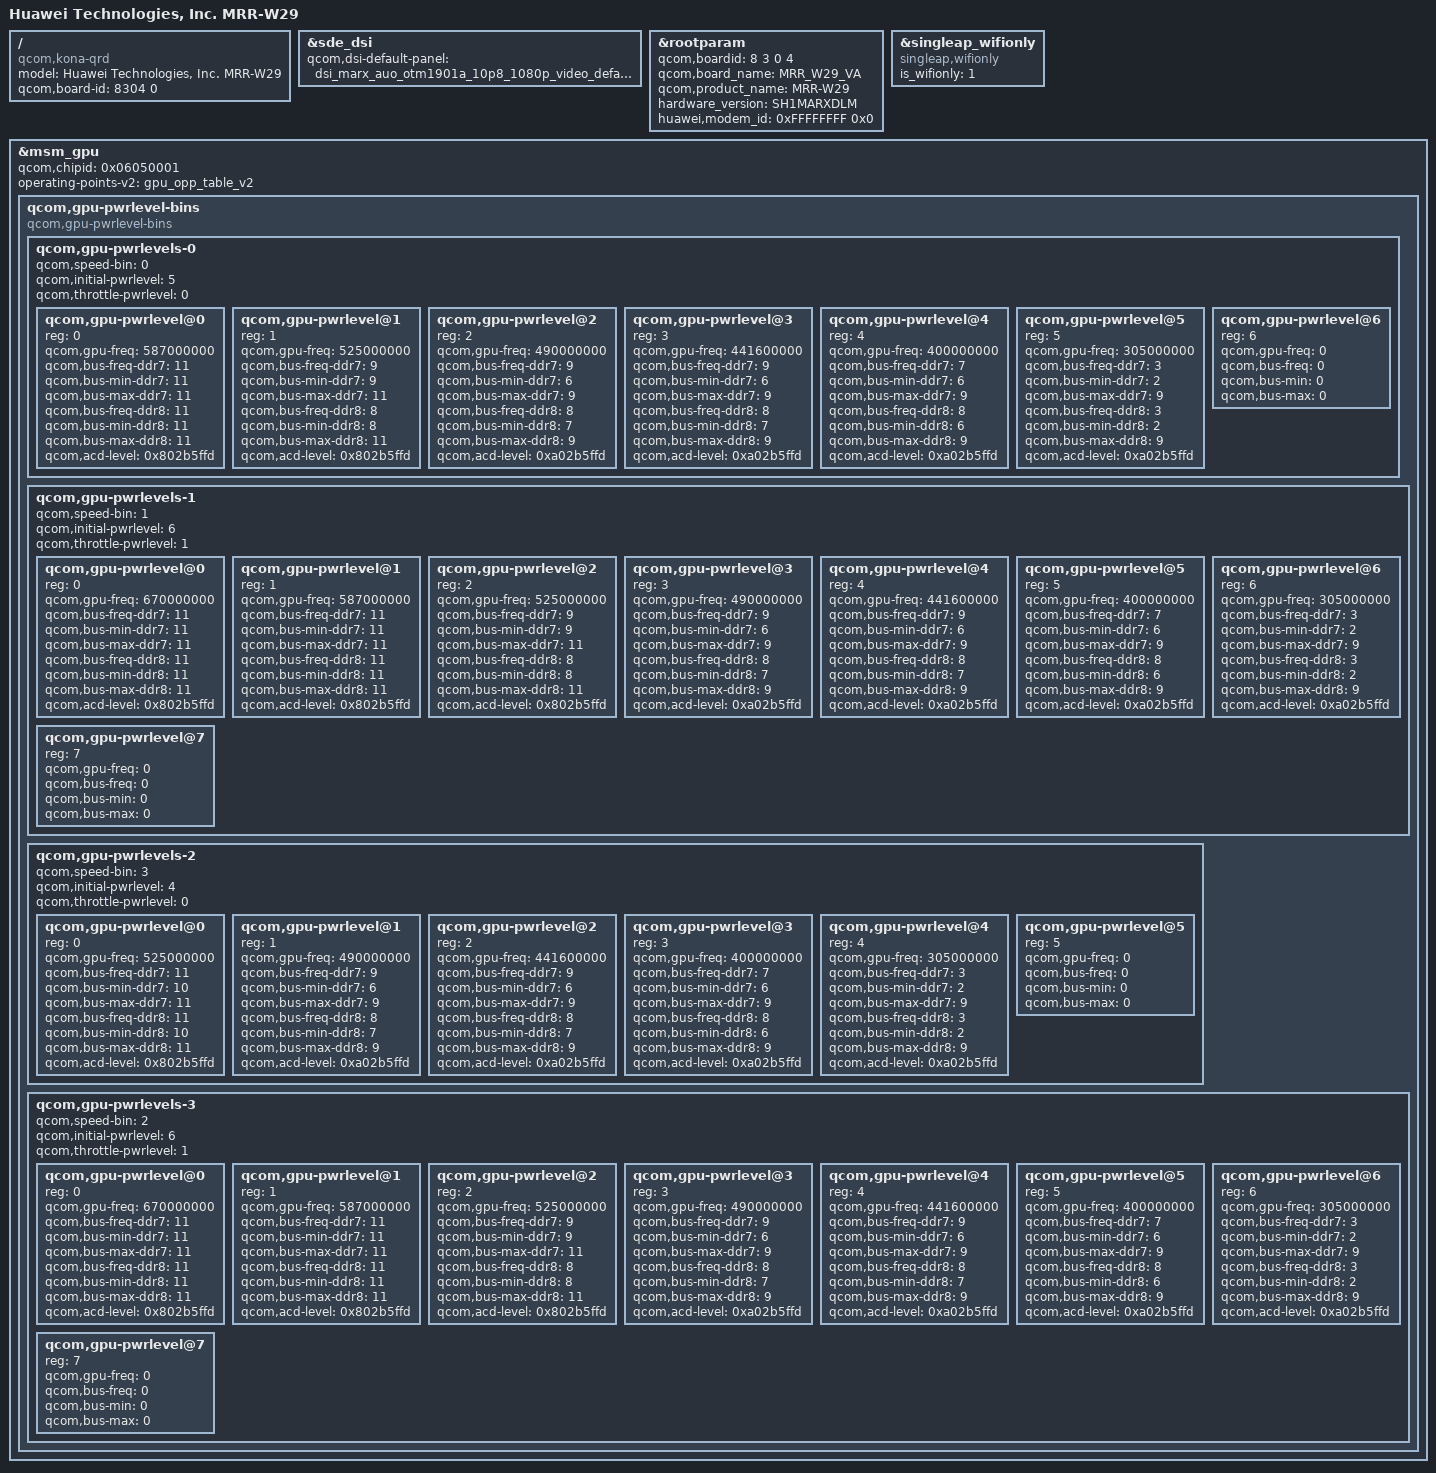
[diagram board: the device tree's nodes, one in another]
/dts-v1/;
/plugin/;

#include "../../common/common.dtsi"
#include "huawei-lcd.dtsi"
#include "huawei_tp.dtsi"
#include "../common/huawei_charger.dtsi"
#include "../common/huawei_pcie.dtsi"
#include "huawei-audio.dtsi"
#include "huawei-sensor.dtsi"
#include "huawei-vibrator.dtsi"
#include "huawei_antenna_board_detect.dtsi"
#include "huawei_camera.dtsi"
#include "huawei_wifi.dtsi"
#include "huawei_storage.dtsi"
#include "huawei_dev_detect.dtsi"
#include "../common/huawei_usb.dtsi"

/ {
    /* bsp_replace_info @ model = "Huawei Technologies, Inc. %product_name%"; */
    model = "Huawei Technologies, Inc. MRR-W29";
    compatible = "qcom,kona-qrd", "qcom,kona", "qcom,qrd";
    /* bsp_replace_info @ qcom,board-id = <%boardid% 0>; */
    qcom,board-id = <8304 0>;
};

&sde_dsi {
    qcom,dsi-default-panel = <&dsi_marx_auo_otm1901a_10p8_1080p_video_default>;
};

&rootparam {
    /* bsp_replace_info @ qcom,boardid = <%boardid_split%>; */
    /* auto_key_info @ name: boardid type: uint32 default: 0 */
    qcom,boardid = <8 3 0 4>;
    /* bsp_replace_info @ qcom,board_name = "%board_name%"; */
    qcom,board_name = "MRR_W29_VA";
    /* bsp_replace_info @ qcom,product_name = "%product_name%"; */
    qcom,product_name = "MRR-W29";
    /* bsp_replace_info @ hardware_version = "%hardware_version%"; */
    hardware_version = "SH1MARXDLM";
    /* bsp_replace_info @ huawei,modem_id = <%modem_id% 0x0>; */
    huawei,modem_id = <0xFFFFFFFF 0x0>;
};

&singleap_wifionly {
    compatible = "singleap,wifionly";
    is_wifionly = "1";
    status = "ok";
};

&msm_gpu {
	qcom,chipid = <0x06050001>;

	/* GPU OPP data */
	operating-points-v2 = <&gpu_opp_table_v2>;

	/delete-property/qcom,initial-pwrlevel;
	/delete-node/qcom,gpu-pwrlevels;

	/* Power levels bins */
	qcom,gpu-pwrlevel-bins {
		compatible="qcom,gpu-pwrlevel-bins";
		#address-cells = <1>;
		#size-cells = <0>;

		 qcom,gpu-pwrlevels-0 {
			#address-cells = <1>;
			#size-cells = <0>;
			qcom,speed-bin = <0>;
			qcom,initial-pwrlevel = <5>;
			qcom,throttle-pwrlevel = <0>;

			qcom,gpu-pwrlevel@0 {
				reg = <0>;
				qcom,gpu-freq = <587000000>;
				qcom,bus-freq-ddr7 = <11>;
				qcom,bus-min-ddr7 = <11>;
				qcom,bus-max-ddr7 = <11>;

				qcom,bus-freq-ddr8 = <11>;
				qcom,bus-min-ddr8 = <11>;
				qcom,bus-max-ddr8 = <11>;

				qcom,acd-level = <0x802b5ffd>;
			};

			qcom,gpu-pwrlevel@1 {
				reg = <1>;
				qcom,gpu-freq = <525000000>;
				qcom,bus-freq-ddr7 = <9>;
				qcom,bus-min-ddr7 = <9>;
				qcom,bus-max-ddr7 = <11>;

				qcom,bus-freq-ddr8 = <8>;
				qcom,bus-min-ddr8 = <8>;
				qcom,bus-max-ddr8 = <11>;

				qcom,acd-level = <0x802b5ffd>;
			};

			qcom,gpu-pwrlevel@2 {
				reg = <2>;
				qcom,gpu-freq = <490000000>;
				qcom,bus-freq-ddr7 = <9>;
				qcom,bus-min-ddr7 = <6>;
				qcom,bus-max-ddr7 = <9>;

				qcom,bus-freq-ddr8 = <8>;
				qcom,bus-min-ddr8 = <7>;
				qcom,bus-max-ddr8 = <9>;

				qcom,acd-level = <0xa02b5ffd>;
			};

			qcom,gpu-pwrlevel@3 {
				reg = <3>;
				qcom,gpu-freq = <441600000>;
				qcom,bus-freq-ddr7 = <9>;
				qcom,bus-min-ddr7 = <6>;
				qcom,bus-max-ddr7 = <9>;

				qcom,bus-freq-ddr8 = <8>;
				qcom,bus-min-ddr8 = <7>;
				qcom,bus-max-ddr8 = <9>;

				qcom,acd-level = <0xa02b5ffd>;
			};

			qcom,gpu-pwrlevel@4 {
				reg = <4>;
				qcom,gpu-freq = <400000000>;
				qcom,bus-freq-ddr7 = <7>;
				qcom,bus-min-ddr7 = <6>;
				qcom,bus-max-ddr7 = <9>;

				qcom,bus-freq-ddr8 = <8>;
				qcom,bus-min-ddr8 = <6>;
				qcom,bus-max-ddr8 = <9>;

				qcom,acd-level = <0xa02b5ffd>;
			};

			qcom,gpu-pwrlevel@5 {
				reg = <5>;
				qcom,gpu-freq = <305000000>;
				qcom,bus-freq-ddr7 = <3>;
				qcom,bus-min-ddr7 = <2>;
				qcom,bus-max-ddr7 = <9>;

				qcom,bus-freq-ddr8 = <3>;
				qcom,bus-min-ddr8 = <2>;
				qcom,bus-max-ddr8 = <9>;

				qcom,acd-level = <0xa02b5ffd>;
			};

			qcom,gpu-pwrlevel@6 {
				reg = <6>;
				qcom,gpu-freq = <0>;
				qcom,bus-freq = <0>;
				qcom,bus-min = <0>;
				qcom,bus-max = <0>;
			};
		};

		qcom,gpu-pwrlevels-1 {
			#address-cells = <1>;
			#size-cells = <0>;
			qcom,speed-bin = <1>;
			qcom,initial-pwrlevel = <6>;
			qcom,throttle-pwrlevel = <1>;

			qcom,gpu-pwrlevel@0 {
				reg = <0>;
				qcom,gpu-freq = <670000000>;
				qcom,bus-freq-ddr7 = <11>;
				qcom,bus-min-ddr7 = <11>;
				qcom,bus-max-ddr7 = <11>;

				qcom,bus-freq-ddr8 = <11>;
				qcom,bus-min-ddr8 = <11>;
				qcom,bus-max-ddr8 = <11>;

				qcom,acd-level = <0x802b5ffd>;
			};

			qcom,gpu-pwrlevel@1 {
				reg = <1>;
				qcom,gpu-freq = <587000000>;
				qcom,bus-freq-ddr7 = <11>;
				qcom,bus-min-ddr7 = <11>;
				qcom,bus-max-ddr7 = <11>;

				qcom,bus-freq-ddr8 = <11>;
				qcom,bus-min-ddr8 = <11>;
				qcom,bus-max-ddr8 = <11>;

				qcom,acd-level = <0x802b5ffd>;
			};

			qcom,gpu-pwrlevel@2 {
				reg = <2>;
				qcom,gpu-freq = <525000000>;
				qcom,bus-freq-ddr7 = <9>;
				qcom,bus-min-ddr7 = <9>;
				qcom,bus-max-ddr7 = <11>;

				qcom,bus-freq-ddr8 = <8>;
				qcom,bus-min-ddr8 = <8>;
				qcom,bus-max-ddr8 = <11>;

				qcom,acd-level = <0x802b5ffd>;
			};

			qcom,gpu-pwrlevel@3 {
				reg = <3>;
				qcom,gpu-freq = <490000000>;
				qcom,bus-freq-ddr7 = <9>;
				qcom,bus-min-ddr7 = <6>;
				qcom,bus-max-ddr7 = <9>;

				qcom,bus-freq-ddr8 = <8>;
				qcom,bus-min-ddr8 = <7>;
				qcom,bus-max-ddr8 = <9>;

				qcom,acd-level = <0xa02b5ffd>;
				};

			qcom,gpu-pwrlevel@4 {
				reg = <4>;
				qcom,gpu-freq = <441600000>;
				qcom,bus-freq-ddr7 = <9>;
				qcom,bus-min-ddr7 = <6>;
				qcom,bus-max-ddr7 = <9>;

				qcom,bus-freq-ddr8 = <8>;
				qcom,bus-min-ddr8 = <7>;
				qcom,bus-max-ddr8 = <9>;

				qcom,acd-level = <0xa02b5ffd>;
			};

			qcom,gpu-pwrlevel@5 {
				reg = <5>;
				qcom,gpu-freq = <400000000>;
				qcom,bus-freq-ddr7 = <7>;
				qcom,bus-min-ddr7 = <6>;
				qcom,bus-max-ddr7 = <9>;

				qcom,bus-freq-ddr8 = <8>;
				qcom,bus-min-ddr8 = <6>;
				qcom,bus-max-ddr8 = <9>;

				qcom,acd-level = <0xa02b5ffd>;
			};

			qcom,gpu-pwrlevel@6 {
				reg = <6>;
				qcom,gpu-freq = <305000000>;
				qcom,bus-freq-ddr7 = <3>;
				qcom,bus-min-ddr7 = <2>;
				qcom,bus-max-ddr7 = <9>;

				qcom,bus-freq-ddr8 = <3>;
				qcom,bus-min-ddr8 = <2>;
				qcom,bus-max-ddr8 = <9>;

				qcom,acd-level = <0xa02b5ffd>;
			};

			qcom,gpu-pwrlevel@7 {
				reg = <7>;
				qcom,gpu-freq = <0>;
				qcom,bus-freq = <0>;
				qcom,bus-min = <0>;
				qcom,bus-max = <0>;
			};
		};

		qcom,gpu-pwrlevels-2 {
			#address-cells = <1>;
			#size-cells = <0>;
			qcom,speed-bin = <3>;
			qcom,initial-pwrlevel = <4>;
			qcom,throttle-pwrlevel = <0>;

			qcom,gpu-pwrlevel@0 {
				reg = <0>;
				qcom,gpu-freq = <525000000>;
				qcom,bus-freq-ddr7 = <11>;
				qcom,bus-min-ddr7 = <10>;
				qcom,bus-max-ddr7 = <11>;

				qcom,bus-freq-ddr8 = <11>;
				qcom,bus-min-ddr8 = <10>;
				qcom,bus-max-ddr8 = <11>;

				qcom,acd-level = <0x802b5ffd>;
			};

			qcom,gpu-pwrlevel@1 {
				reg = <1>;
				qcom,gpu-freq = <490000000>;
				qcom,bus-freq-ddr7 = <9>;
				qcom,bus-min-ddr7 = <6>;
				qcom,bus-max-ddr7 = <9>;

				qcom,bus-freq-ddr8 = <8>;
				qcom,bus-min-ddr8 = <7>;
				qcom,bus-max-ddr8 = <9>;

				qcom,acd-level = <0xa02b5ffd>;
			};

			qcom,gpu-pwrlevel@2 {
				reg = <2>;
				qcom,gpu-freq = <441600000>;
				qcom,bus-freq-ddr7 = <9>;
				qcom,bus-min-ddr7 = <6>;
				qcom,bus-max-ddr7 = <9>;

				qcom,bus-freq-ddr8 = <8>;
				qcom,bus-min-ddr8 = <7>;
				qcom,bus-max-ddr8 = <9>;

				qcom,acd-level = <0xa02b5ffd>;
			};

			qcom,gpu-pwrlevel@3 {
				reg = <3>;
				qcom,gpu-freq = <400000000>;
				qcom,bus-freq-ddr7 = <7>;
				qcom,bus-min-ddr7 = <6>;
				qcom,bus-max-ddr7 = <9>;

				qcom,bus-freq-ddr8 = <8>;
				qcom,bus-min-ddr8 = <6>;
				qcom,bus-max-ddr8 = <9>;

				qcom,acd-level = <0xa02b5ffd>;
			};

			qcom,gpu-pwrlevel@4 {
				reg = <4>;
				qcom,gpu-freq = <305000000>;
				qcom,bus-freq-ddr7 = <3>;
				qcom,bus-min-ddr7 = <2>;
				qcom,bus-max-ddr7 = <9>;

				qcom,bus-freq-ddr8 = <3>;
				qcom,bus-min-ddr8 = <2>;
				qcom,bus-max-ddr8 = <9>;

				qcom,acd-level = <0xa02b5ffd>;
			};

			qcom,gpu-pwrlevel@5 {
				reg = <5>;
				qcom,gpu-freq = <0>;
				qcom,bus-freq = <0>;
				qcom,bus-min = <0>;
				qcom,bus-max = <0>;
			};
		};

		qcom,gpu-pwrlevels-3 {
			#address-cells = <1>;
			#size-cells = <0>;
			qcom,speed-bin = <2>;
			qcom,initial-pwrlevel = <6>;
			qcom,throttle-pwrlevel = <1>;

			qcom,gpu-pwrlevel@0 {
				reg = <0>;
				qcom,gpu-freq = <670000000>;
				qcom,bus-freq-ddr7 = <11>;
				qcom,bus-min-ddr7 = <11>;
				qcom,bus-max-ddr7 = <11>;

				qcom,bus-freq-ddr8 = <11>;
				qcom,bus-min-ddr8 = <11>;
				qcom,bus-max-ddr8 = <11>;

				qcom,acd-level = <0x802b5ffd>;
			};

			qcom,gpu-pwrlevel@1 {
				reg = <1>;
				qcom,gpu-freq = <587000000>;
				qcom,bus-freq-ddr7 = <11>;
				qcom,bus-min-ddr7 = <11>;
				qcom,bus-max-ddr7 = <11>;

				qcom,bus-freq-ddr8 = <11>;
				qcom,bus-min-ddr8 = <11>;
				qcom,bus-max-ddr8 = <11>;

				qcom,acd-level = <0x802b5ffd>;
			};

			qcom,gpu-pwrlevel@2 {
				reg = <2>;
				qcom,gpu-freq = <525000000>;
				qcom,bus-freq-ddr7 = <9>;
				qcom,bus-min-ddr7 = <9>;
				qcom,bus-max-ddr7 = <11>;

				qcom,bus-freq-ddr8 = <8>;
				qcom,bus-min-ddr8 = <8>;
				qcom,bus-max-ddr8 = <11>;

				qcom,acd-level = <0x802b5ffd>;
			};

			qcom,gpu-pwrlevel@3 {
				reg = <3>;
				qcom,gpu-freq = <490000000>;
				qcom,bus-freq-ddr7 = <9>;
				qcom,bus-min-ddr7 = <6>;
				qcom,bus-max-ddr7 = <9>;

				qcom,bus-freq-ddr8 = <8>;
				qcom,bus-min-ddr8 = <7>;
				qcom,bus-max-ddr8 = <9>;

				qcom,acd-level = <0xa02b5ffd>;
			};

			qcom,gpu-pwrlevel@4 {
				reg = <4>;
				qcom,gpu-freq = <441600000>;
				qcom,bus-freq-ddr7 = <9>;
				qcom,bus-min-ddr7 = <6>;
				qcom,bus-max-ddr7 = <9>;

				qcom,bus-freq-ddr8 = <8>;
				qcom,bus-min-ddr8 = <7>;
				qcom,bus-max-ddr8 = <9>;

				qcom,acd-level = <0xa02b5ffd>;
			};

			qcom,gpu-pwrlevel@5 {
				reg = <5>;
				qcom,gpu-freq = <400000000>;
				qcom,bus-freq-ddr7 = <7>;
				qcom,bus-min-ddr7 = <6>;
				qcom,bus-max-ddr7 = <9>;

				qcom,bus-freq-ddr8 = <8>;
				qcom,bus-min-ddr8 = <6>;
				qcom,bus-max-ddr8 = <9>;

				qcom,acd-level = <0xa02b5ffd>;
			};

			qcom,gpu-pwrlevel@6 {
				reg = <6>;
				qcom,gpu-freq = <305000000>;
				qcom,bus-freq-ddr7 = <3>;
				qcom,bus-min-ddr7 = <2>;
				qcom,bus-max-ddr7 = <9>;

				qcom,bus-freq-ddr8 = <3>;
				qcom,bus-min-ddr8 = <2>;
				qcom,bus-max-ddr8 = <9>;

				qcom,acd-level = <0xa02b5ffd>;
			};

			qcom,gpu-pwrlevel@7 {
				reg = <7>;
				qcom,gpu-freq = <0>;
				qcom,bus-freq = <0>;
				qcom,bus-min = <0>;
				qcom,bus-max = <0>;
			};
		};
	};
};

